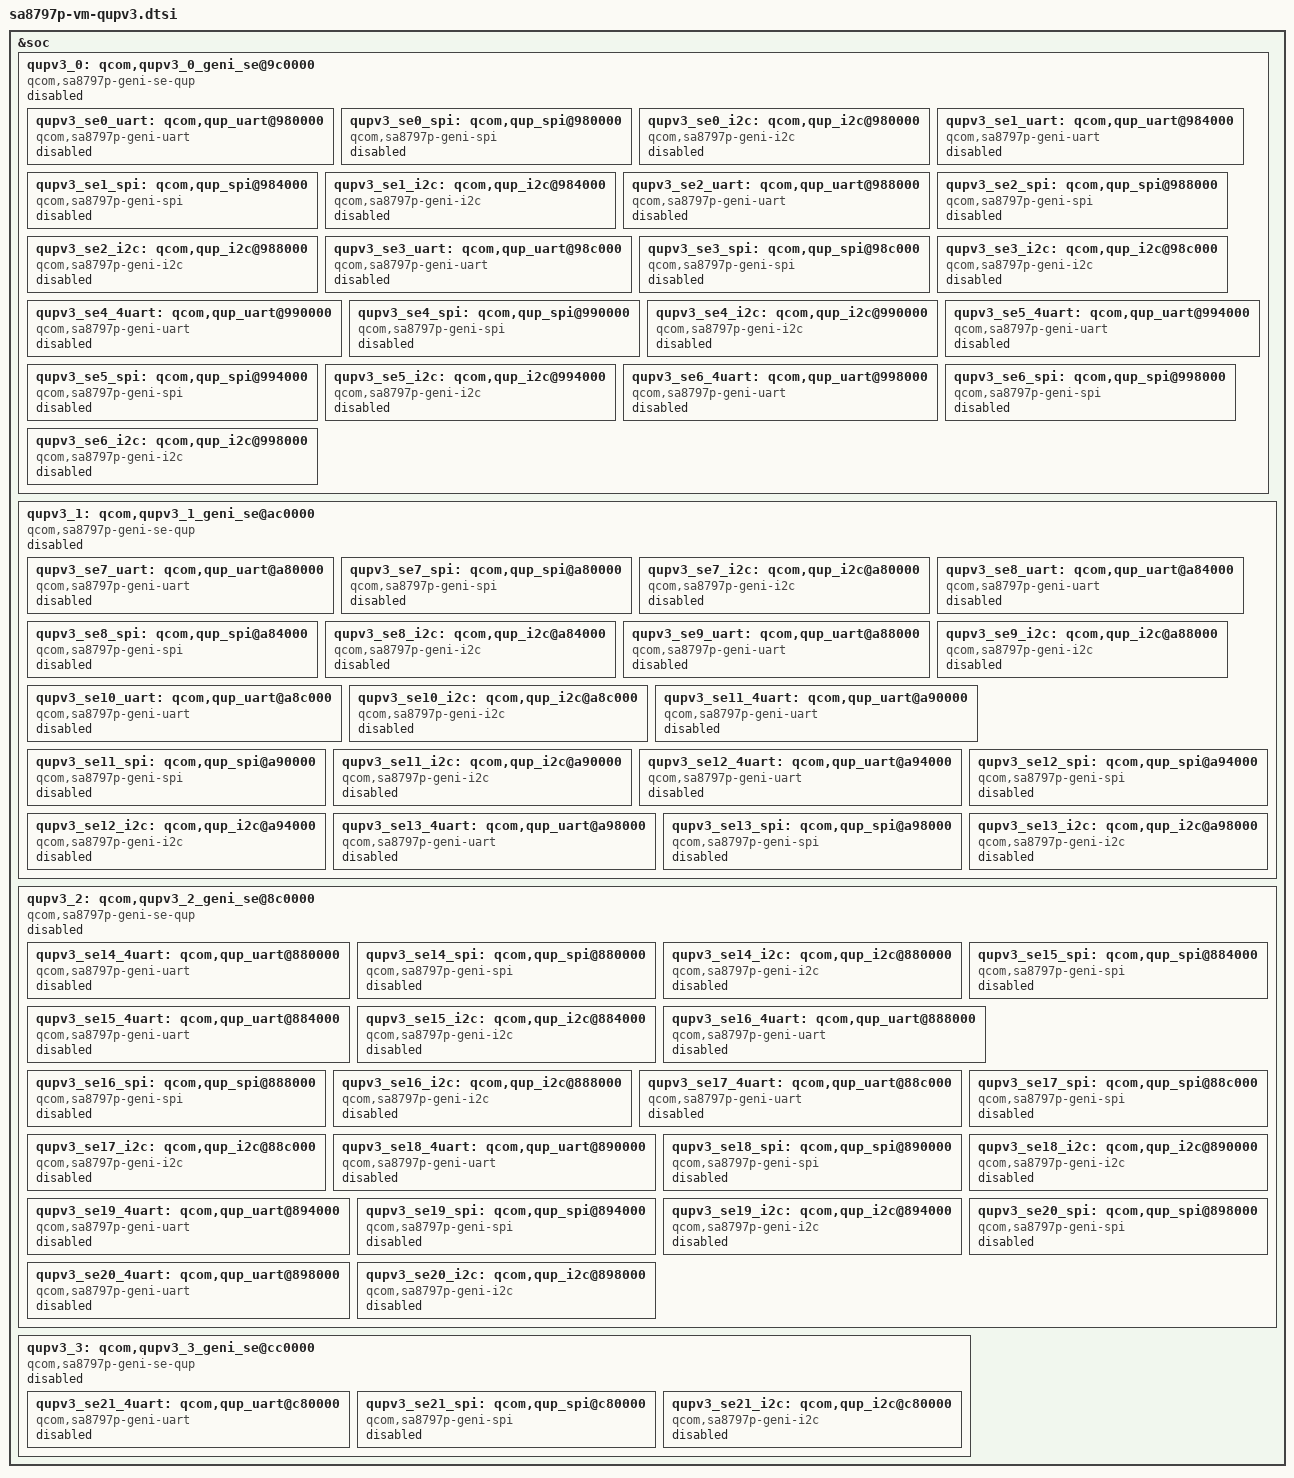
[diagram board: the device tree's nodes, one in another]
// SPDX-License-Identifier: BSD-3-Clause
/*
 * Copyright (c) Qualcomm Technologies, Inc. and/or its subsidiaries.
 */

/* Note :
 * power-domains = <&scmi_power x>, <&scmi_perf x>;
 * These values should be adjusted as per PVM (QNX/Linux) while configuring passthrough.
 */

&soc {
	/* QUPv3_0  wrapper  instance */
	qupv3_0: qcom,qupv3_0_geni_se@9c0000 {
		compatible = "qcom,sa8797p-geni-se-qup", "qcom,sa8255p-geni-se-qup";
		reg = <0x9c0000 0x1000>;
		#address-cells = <1>;
		#size-cells = <1>;
		ranges;
		iommus = <&apps_smmu_2 0x1018 0x0>;
		qcom,iommu-dma = "default";
		status = "disabled";

		qupv3_se0_uart: qcom,qup_uart@980000 {
			compatible = "qcom,sa8797p-geni-uart", "qcom,sa8255p-geni-uart";
			reg = <0x980000 0x3000>;
			interrupts = <GIC_SPI 314 IRQ_TYPE_LEVEL_HIGH>;
			power-domains = <&scmi_power 0>, <&scmi_perf 0>;
			power-domain-names = "power", "perf";
			status = "disabled";
		};

		qupv3_se0_spi: qcom,qup_spi@980000 {
			compatible = "qcom,sa8797p-geni-spi", "qcom,sa8255p-geni-spi";
			reg = <0x980000 0x3000>;
			interrupts = <GIC_SPI 314 IRQ_TYPE_LEVEL_HIGH>;
			power-domains = <&scmi_power 0>, <&scmi_perf 0>;
			power-domain-names = "power", "perf";
			status = "disabled";
		};

		qupv3_se0_i2c: qcom,qup_i2c@980000 {
			compatible = "qcom,sa8797p-geni-i2c", "qcom,sa8255p-geni-i2c";
			reg = <0x980000 0x3000>;
			interrupts = <GIC_SPI 314 IRQ_TYPE_LEVEL_HIGH>;
			power-domains = <&scmi_power 0>;
			status = "disabled";
		};

		qupv3_se1_uart: qcom,qup_uart@984000 {
			compatible = "qcom,sa8797p-geni-uart", "qcom,sa8255p-geni-uart";
			reg = <0x984000 0x3000>;
			interrupts = <GIC_SPI 513 IRQ_TYPE_LEVEL_HIGH>;
			power-domains = <&scmi_power 1>, <&scmi_perf 1>;
			power-domain-names = "power", "perf";
			status = "disabled";
		};

		qupv3_se1_spi: qcom,qup_spi@984000 {
			compatible = "qcom,sa8797p-geni-spi", "qcom,sa8255p-geni-spi";
			reg = <0x984000 0x3000>;
			interrupts = <GIC_SPI 513 IRQ_TYPE_LEVEL_HIGH>;
			power-domains = <&scmi_power 1>, <&scmi_perf 1>;
			power-domain-names = "power", "perf";
			status = "disabled";
		};

		qupv3_se1_i2c: qcom,qup_i2c@984000 {
			compatible = "qcom,sa8797p-geni-i2c", "qcom,sa8255p-geni-i2c";
			reg = <0x984000 0x3000>;
			interrupts = <GIC_SPI 513 IRQ_TYPE_LEVEL_HIGH>;
			power-domains = <&scmi_power 1>;
			status = "disabled";
		};

		qupv3_se2_uart: qcom,qup_uart@988000 {
			compatible = "qcom,sa8797p-geni-uart", "qcom,sa8255p-geni-uart";
			reg = <0x988000 0x3000>;
			interrupts = <GIC_SPI 514 IRQ_TYPE_LEVEL_HIGH>;
			power-domains = <&scmi_power 2>, <&scmi_perf 2>;
			power-domain-names = "power", "perf";
			status = "disabled";
		};

		qupv3_se2_spi: qcom,qup_spi@988000 {
			compatible = "qcom,sa8797p-geni-spi", "qcom,sa8255p-geni-spi";
			reg = <0x988000 0x3000>;
			interrupts = <GIC_SPI 514 IRQ_TYPE_LEVEL_HIGH>;
			power-domains = <&scmi_power 2>, <&scmi_perf 2>;
			power-domain-names = "power", "perf";
			status = "disabled";
		};

		qupv3_se2_i2c: qcom,qup_i2c@988000 {
			compatible = "qcom,sa8797p-geni-i2c", "qcom,sa8255p-geni-i2c";
			reg = <0x988000 0x3000>;
			interrupts = <GIC_SPI 514 IRQ_TYPE_LEVEL_HIGH>;
			power-domains = <&scmi_power 2>;
			status = "disabled";
		};

		qupv3_se3_uart: qcom,qup_uart@98c000 {
			compatible = "qcom,sa8797p-geni-uart", "qcom,sa8255p-geni-uart";
			reg = <0x98c000 0x3000>;
			interrupts = <GIC_SPI 515 IRQ_TYPE_LEVEL_HIGH>;
			power-domains = <&scmi_power 3>, <&scmi_perf 3>;
			power-domain-names = "power", "perf";
			status = "disabled";
		};

		qupv3_se3_spi: qcom,qup_spi@98c000 {
			compatible = "qcom,sa8797p-geni-spi", "qcom,sa8255p-geni-spi";
			reg = <0x98c000 0x3000>;
			interrupts = <GIC_SPI 515 IRQ_TYPE_LEVEL_HIGH>;
			power-domains = <&scmi_power 3>, <&scmi_perf 3>;
			power-domain-names = "power", "perf";
			status = "disabled";
		};

		qupv3_se3_i2c: qcom,qup_i2c@98c000 {
			compatible = "qcom,sa8797p-geni-i2c", "qcom,sa8255p-geni-i2c";
			reg = <0x98c000 0x3000>;
			interrupts = <GIC_SPI 515 IRQ_TYPE_LEVEL_HIGH>;
			power-domains = <&scmi_power 3>;
			status = "disabled";
		};

		qupv3_se4_4uart: qcom,qup_uart@990000 {
			compatible = "qcom,sa8797p-geni-uart", "qcom,sa8255p-geni-uart";
			reg = <0x990000 0x3000>;
			interrupts = <GIC_SPI 516 IRQ_TYPE_LEVEL_HIGH>;
			power-domains = <&scmi_power 4>, <&scmi_perf 4>;
			power-domain-names = "power", "perf";
			status = "disabled";
		};

		qupv3_se4_spi: qcom,qup_spi@990000 {
			compatible = "qcom,sa8797p-geni-spi", "qcom,sa8255p-geni-spi";
			reg = <0x990000 0x3000>;
			interrupts = <GIC_SPI 516 IRQ_TYPE_LEVEL_HIGH>;
			power-domains = <&scmi_power 4>, <&scmi_perf 4>;
			power-domain-names = "power", "perf";
			status = "disabled";
		};

		qupv3_se4_i2c: qcom,qup_i2c@990000 {
			compatible = "qcom,sa8797p-geni-i2c", "qcom,sa8255p-geni-i2c";
			reg = <0x990000 0x3000>;
			interrupts = <GIC_SPI 516 IRQ_TYPE_LEVEL_HIGH>;
			power-domains = <&scmi_power 4>;
			status = "disabled";
		};

		qupv3_se5_4uart: qcom,qup_uart@994000 {
			compatible = "qcom,sa8797p-geni-uart", "qcom,sa8255p-geni-uart";
			reg = <0x994000 0x3000>;
			interrupts = <GIC_SPI 517 IRQ_TYPE_LEVEL_HIGH>;
			power-domains = <&scmi_power 5>, <&scmi_perf 5>;
			power-domain-names = "power", "perf";
			status = "disabled";
		};

		qupv3_se5_spi: qcom,qup_spi@994000 {
			compatible = "qcom,sa8797p-geni-spi", "qcom,sa8255p-geni-spi";
			reg = <0x994000 0x3000>;
			interrupts = <GIC_SPI 517 IRQ_TYPE_LEVEL_HIGH>;
			power-domains = <&scmi_power 5>, <&scmi_perf 5>;
			power-domain-names = "power", "perf";
			status = "disabled";
		};

		qupv3_se5_i2c: qcom,qup_i2c@994000 {
			compatible = "qcom,sa8797p-geni-i2c", "qcom,sa8255p-geni-i2c";
			reg = <0x994000 0x3000>;
			interrupts = <GIC_SPI 517 IRQ_TYPE_LEVEL_HIGH>;
			power-domains = <&scmi_power 5>;
			status = "disabled";
		};

		qupv3_se6_4uart: qcom,qup_uart@998000 {
			compatible = "qcom,sa8797p-geni-uart", "qcom,sa8255p-geni-uart";
			reg = <0x998000 0x3000>;
			interrupts = <GIC_SPI 518 IRQ_TYPE_LEVEL_HIGH>;
			power-domains = <&scmi_power 6>, <&scmi_perf 6>;
			power-domain-names = "power", "perf";
			status = "disabled";
		};

		qupv3_se6_spi: qcom,qup_spi@998000 {
			compatible = "qcom,sa8797p-geni-spi", "qcom,sa8255p-geni-spi";
			reg = <0x998000 0x3000>;
			interrupts = <GIC_SPI 518 IRQ_TYPE_LEVEL_HIGH>;
			power-domains = <&scmi_power 6>, <&scmi_perf 6>;
			power-domain-names = "power", "perf";
			status = "disabled";
		};

		qupv3_se6_i2c: qcom,qup_i2c@998000 {
			compatible = "qcom,sa8797p-geni-i2c", "qcom,sa8255p-geni-i2c";
			reg = <0x998000 0x3000>;
			interrupts = <GIC_SPI 518 IRQ_TYPE_LEVEL_HIGH>;
			power-domains = <&scmi_power 6>;
			status = "disabled";
		};
	};

	/* QUPv3_1  wrapper  instance */
	qupv3_1: qcom,qupv3_1_geni_se@ac0000 {
		compatible = "qcom,sa8797p-geni-se-qup", "qcom,sa8255p-geni-se-qup";
		reg = <0xac0000 0x1000>;
		#address-cells = <1>;
		#size-cells = <1>;
		ranges;
		iommus = <&apps_smmu_2 0x1058 0x0>;
		qcom,iommu-dma = "default";
		status = "disabled";

		qupv3_se7_uart: qcom,qup_uart@a80000 {
			compatible = "qcom,sa8797p-geni-uart", "qcom,sa8255p-geni-uart";
			reg = <0xa80000 0x3000>;
			interrupts = <GIC_SPI 353 IRQ_TYPE_LEVEL_HIGH>;
			power-domains = <&scmi_power 7>, <&scmi_perf 7>;
			power-domain-names = "power", "perf";
			status = "disabled";
		};

		qupv3_se7_spi: qcom,qup_spi@a80000 {
			compatible = "qcom,sa8797p-geni-spi", "qcom,sa8255p-geni-spi";
			reg = <0xa80000 0x3000>;
			interrupts = <GIC_SPI 353 IRQ_TYPE_LEVEL_HIGH>;
			power-domains = <&scmi_power 7>, <&scmi_perf 7>;
			power-domain-names = "power", "perf";
			status = "disabled";
		};

		qupv3_se7_i2c: qcom,qup_i2c@a80000 {
			compatible = "qcom,sa8797p-geni-i2c", "qcom,sa8255p-geni-i2c";
			reg = <0xa80000 0x3000>;
			interrupts = <GIC_SPI 353 IRQ_TYPE_LEVEL_HIGH>;
			power-domains = <&scmi_power 7>;
			status = "disabled";
		};

		qupv3_se8_uart: qcom,qup_uart@a84000 {
			compatible = "qcom,sa8797p-geni-uart", "qcom,sa8255p-geni-uart";
			reg = <0xa84000 0x3000>;
			interrupts = <GIC_SPI 354 IRQ_TYPE_LEVEL_HIGH>;
			power-domains = <&scmi_power 8>, <&scmi_perf 8>;
			power-domain-names = "power", "perf";
			status = "disabled";
		};

		qupv3_se8_spi: qcom,qup_spi@a84000 {
			compatible = "qcom,sa8797p-geni-spi", "qcom,sa8255p-geni-spi";
			reg = <0xa84000 0x3000>;
			interrupts = <GIC_SPI 354 IRQ_TYPE_LEVEL_HIGH>;
			power-domains = <&scmi_power 8>, <&scmi_perf 8>;
			power-domain-names = "power", "perf";
			status = "disabled";
		};

		qupv3_se8_i2c: qcom,qup_i2c@a84000 {
			compatible = "qcom,sa8797p-geni-i2c", "qcom,sa8255p-geni-i2c";
			reg = <0xa84000 0x3000>;
			interrupts = <GIC_SPI 354 IRQ_TYPE_LEVEL_HIGH>;
			power-domains = <&scmi_power 8>;
			status = "disabled";
		};

		qupv3_se9_uart: qcom,qup_uart@a88000 {
			compatible = "qcom,sa8797p-geni-uart", "qcom,sa8255p-geni-uart";
			reg = <0xa88000 0x3000>;
			interrupts = <GIC_SPI 355 IRQ_TYPE_LEVEL_HIGH>;
			power-domains = <&scmi_power 9>, <&scmi_perf 9>;
			power-domain-names = "power", "perf";
			status = "disabled";
		};

		qupv3_se9_i2c: qcom,qup_i2c@a88000 {
			compatible = "qcom,sa8797p-geni-i2c", "qcom,sa8255p-geni-i2c";
			reg = <0xa88000 0x3000>;
			interrupts = <GIC_SPI 355 IRQ_TYPE_LEVEL_HIGH>;
			power-domains = <&scmi_power 9>;
			status = "disabled";
		};

		qupv3_se10_uart: qcom,qup_uart@a8c000 {
			compatible = "qcom,sa8797p-geni-uart", "qcom,sa8255p-geni-uart";
			reg = <0xa8c000 0x3000>;
			interrupts = <GIC_SPI 356 IRQ_TYPE_LEVEL_HIGH>;
			power-domains = <&scmi_power 10>, <&scmi_perf 10>;
			power-domain-names = "power", "perf";
			status = "disabled";
		};

		qupv3_se10_i2c: qcom,qup_i2c@a8c000 {
			compatible = "qcom,sa8797p-geni-i2c", "qcom,sa8255p-geni-i2c";
			reg = <0xa8c000 0x3000>;
			interrupts = <GIC_SPI 356 IRQ_TYPE_LEVEL_HIGH>;
			power-domains = <&scmi_power 10>;
			status = "disabled";
		};

		qupv3_se11_4uart: qcom,qup_uart@a90000 {
			compatible = "qcom,sa8797p-geni-uart", "qcom,sa8255p-geni-uart";
			reg = <0xa90000 0x3000>;
			interrupts = <GIC_SPI 357 IRQ_TYPE_LEVEL_HIGH>;
			power-domains = <&scmi_power 11>, <&scmi_perf 11>;
			power-domain-names = "power", "perf";
			status = "disabled";
		};

		qupv3_se11_spi: qcom,qup_spi@a90000 {
			compatible = "qcom,sa8797p-geni-spi", "qcom,sa8255p-geni-spi";
			reg = <0xa90000 0x3000>;
			interrupts = <GIC_SPI 357 IRQ_TYPE_LEVEL_HIGH>;
			power-domains = <&scmi_power 11>, <&scmi_perf 11>;
			power-domain-names = "power", "perf";
			status = "disabled";
		};

		qupv3_se11_i2c: qcom,qup_i2c@a90000 {
			compatible = "qcom,sa8797p-geni-i2c", "qcom,sa8255p-geni-i2c";
			reg = <0xa90000 0x3000>;
			interrupts = <GIC_SPI 357 IRQ_TYPE_LEVEL_HIGH>;
			power-domains = <&scmi_power 11>;
			status = "disabled";
		};

		qupv3_se12_4uart: qcom,qup_uart@a94000 {
			compatible = "qcom,sa8797p-geni-uart", "qcom,sa8255p-geni-uart";
			reg = <0xa94000 0x3000>;
			interrupts = <GIC_SPI 358 IRQ_TYPE_LEVEL_HIGH>;
			power-domains = <&scmi_power 12>, <&scmi_perf 12>;
			power-domain-names = "power", "perf";
			status = "disabled";
		};

		qupv3_se12_spi: qcom,qup_spi@a94000 {
			compatible = "qcom,sa8797p-geni-spi", "qcom,sa8255p-geni-spi";
			reg = <0xa94000 0x3000>;
			interrupts = <GIC_SPI 358 IRQ_TYPE_LEVEL_HIGH>;
			power-domains = <&scmi_power 12>, <&scmi_perf 12>;
			power-domain-names = "power", "perf";
			status = "disabled";
		};

		qupv3_se12_i2c: qcom,qup_i2c@a94000 {
			compatible = "qcom,sa8797p-geni-i2c", "qcom,sa8255p-geni-i2c";
			reg = <0xa94000 0x3000>;
			interrupts = <GIC_SPI 358 IRQ_TYPE_LEVEL_HIGH>;
			power-domains = <&scmi_power 12>;
			status = "disabled";
		};

		qupv3_se13_4uart: qcom,qup_uart@a98000 {
			compatible = "qcom,sa8797p-geni-uart", "qcom,sa8255p-geni-uart";
			reg = <0xa98000 0x3000>;
			interrupts = <GIC_SPI 363 IRQ_TYPE_LEVEL_HIGH>;
			power-domains = <&scmi_power 13>, <&scmi_perf 13>;
			power-domain-names = "power", "perf";
			status = "disabled";
		};

		qupv3_se13_spi: qcom,qup_spi@a98000 {
			compatible = "qcom,sa8797p-geni-spi", "qcom,sa8255p-geni-spi";
			reg = <0xa98000 0x3000>;
			interrupts = <GIC_SPI 363 IRQ_TYPE_LEVEL_HIGH>;
			power-domains = <&scmi_power 13>, <&scmi_perf 13>;
			power-domain-names = "power", "perf";
			status = "disabled";
		};

		qupv3_se13_i2c: qcom,qup_i2c@a98000 {
			compatible = "qcom,sa8797p-geni-i2c", "qcom,sa8255p-geni-i2c";
			reg = <0xa98000 0x3000>;
			interrupts = <GIC_SPI 363 IRQ_TYPE_LEVEL_HIGH>;
			power-domains = <&scmi_power 13>;
			status = "disabled";
		};
	};

	/* QUPv3_2  wrapper  instance */
	qupv3_2: qcom,qupv3_2_geni_se@8c0000 {
		compatible = "qcom,sa8797p-geni-se-qup", "qcom,sa8255p-geni-se-qup";
		reg = <0x8c0000 0x1000>;
		#address-cells = <1>;
		#size-cells = <1>;
		ranges;
		iommus = <&apps_smmu_0 0x15b8 0x0>;
		qcom,iommu-dma = "default";
		status = "disabled";

		/* 2BT UART Instance */
		qupv3_se14_4uart: qcom,qup_uart@880000 {
			compatible = "qcom,sa8797p-geni-uart", "qcom,sa8255p-geni-uart";
			reg = <0x880000 0x3000>;
			interrupts = <GIC_SPI 373 IRQ_TYPE_LEVEL_HIGH>;
			power-domains = <&scmi_power 14>, <&scmi_perf 14>;
			power-domain-names = "power", "perf";
			status = "disabled";
		};

		qupv3_se14_spi: qcom,qup_spi@880000 {
			compatible = "qcom,sa8797p-geni-spi", "qcom,sa8255p-geni-spi";
			reg = <0x880000 0x3000>;
			interrupts = <GIC_SPI 373 IRQ_TYPE_LEVEL_HIGH>;
			power-domains = <&scmi_power 14>, <&scmi_perf 14>;
			power-domain-names = "power", "perf";
			status = "disabled";
		};

		qupv3_se14_i2c: qcom,qup_i2c@880000 {
			compatible = "qcom,sa8797p-geni-i2c", "qcom,sa8255p-geni-i2c";
			reg = <0x880000 0x3000>;
			interrupts = <GIC_SPI 373 IRQ_TYPE_LEVEL_HIGH>;
			power-domains = <&scmi_power 14>;
			status = "disabled";
		};

		qupv3_se15_4uart: qcom,qup_uart@884000 {
			compatible = "qcom,sa8797p-geni-uart", "qcom,sa8255p-geni-uart";
			reg = <0x884000 0x3000>;
			interrupts = <GIC_SPI 583 IRQ_TYPE_LEVEL_HIGH>;
			power-domains = <&scmi_power 15>, <&scmi_perf 15>;
			power-domain-names = "power", "perf";
			status = "disabled";
		};

		qupv3_se15_spi: qcom,qup_spi@884000 {
			compatible = "qcom,sa8797p-geni-spi", "qcom,sa8255p-geni-spi";
			reg = <0x884000 0x3000>;
			interrupts = <GIC_SPI 583 IRQ_TYPE_LEVEL_HIGH>;
			power-domains = <&scmi_power 15>, <&scmi_perf 15>;
			power-domain-names = "power", "perf";
			status = "disabled";
		};

		qupv3_se15_i2c: qcom,qup_i2c@884000 {
			compatible = "qcom,sa8797p-geni-i2c", "qcom,sa8255p-geni-i2c";
			reg = <0x884000 0x3000>;
			interrupts = <GIC_SPI 583 IRQ_TYPE_LEVEL_HIGH>;
			power-domains = <&scmi_power 15>;
			status = "disabled";
		};

		qupv3_se16_4uart: qcom,qup_uart@888000 {
			compatible = "qcom,sa8797p-geni-uart", "qcom,sa8255p-geni-uart";
			reg = <0x888000 0x3000>;
			interrupts = <GIC_SPI 584 IRQ_TYPE_LEVEL_HIGH>;
			power-domains = <&scmi_power 16>, <&scmi_perf 16>;
			power-domain-names = "power", "perf";
			status = "disabled";
		};

		qupv3_se16_spi: qcom,qup_spi@888000 {
			compatible = "qcom,sa8797p-geni-spi", "qcom,sa8255p-geni-spi";
			reg = <0x888000 0x3000>;
			interrupts = <GIC_SPI 584 IRQ_TYPE_LEVEL_HIGH>;
			power-domains = <&scmi_power 16>, <&scmi_perf 16>;
			power-domain-names = "power", "perf";
			status = "disabled";
		};

		qupv3_se16_i2c: qcom,qup_i2c@888000 {
			compatible = "qcom,sa8797p-geni-i2c", "qcom,sa8255p-geni-i2c";
			reg = <0x888000 0x3000>;
			interrupts = <GIC_SPI 584 IRQ_TYPE_LEVEL_HIGH>;
			power-domains = <&scmi_power 16>;
			status = "disabled";
		};

		/* BT UART Instance */
		qupv3_se17_4uart: qcom,qup_uart@88c000 {
			compatible = "qcom,sa8797p-geni-uart", "qcom,sa8255p-geni-uart";
			reg = <0x88c000 0x3000>;
			interrupts = <GIC_SPI 585 IRQ_TYPE_LEVEL_HIGH>;
			power-domains = <&scmi_power 17>, <&scmi_perf 17>;
			power-domain-names = "power", "perf";
			status = "disabled";
		};

		qupv3_se17_spi: qcom,qup_spi@88c000 {
			compatible = "qcom,sa8797p-geni-spi", "qcom,sa8255p-geni-spi";
			reg = <0x88c000 0x3000>;
			interrupts = <GIC_SPI 585 IRQ_TYPE_LEVEL_HIGH>;
			power-domains = <&scmi_power 17>, <&scmi_perf 17>;
			power-domain-names = "power", "perf";
			status = "disabled";
		};

		qupv3_se17_i2c: qcom,qup_i2c@88c000 {
			compatible = "qcom,sa8797p-geni-i2c", "qcom,sa8255p-geni-i2c";
			reg = <0x88c000 0x3000>;
			interrupts = <GIC_SPI 585 IRQ_TYPE_LEVEL_HIGH>;
			power-domains = <&scmi_power 17>;
			status = "disabled";
		};

		qupv3_se18_4uart: qcom,qup_uart@890000 {
			compatible = "qcom,sa8797p-geni-uart", "qcom,sa8255p-geni-uart";
			reg = <0x890000 0x3000>;
			interrupts = <GIC_SPI 586 IRQ_TYPE_LEVEL_HIGH>;
			power-domains = <&scmi_power 18>, <&scmi_perf 18>;
			power-domain-names = "power", "perf";
			status = "disabled";
		};

		qupv3_se18_spi: qcom,qup_spi@890000 {
			compatible = "qcom,sa8797p-geni-spi", "qcom,sa8255p-geni-spi";
			reg = <0x890000 0x3000>;
			interrupts = <GIC_SPI 586 IRQ_TYPE_LEVEL_HIGH>;
			power-domains = <&scmi_power 18>, <&scmi_perf 18>;
			power-domain-names = "power", "perf";
			status = "disabled";
		};

		qupv3_se18_i2c: qcom,qup_i2c@890000 {
			compatible = "qcom,sa8797p-geni-i2c", "qcom,sa8255p-geni-i2c";
			reg = <0x890000 0x3000>;
			interrupts = <GIC_SPI 586 IRQ_TYPE_LEVEL_HIGH>;
			power-domains = <&scmi_power 18>;
			status = "disabled";
		};

		qupv3_se19_4uart: qcom,qup_uart@894000 {
			compatible = "qcom,sa8797p-geni-uart", "qcom,sa8255p-geni-uart";
			reg = <0x894000 0x3000>;
			interrupts = <GIC_SPI 587 IRQ_TYPE_LEVEL_HIGH>;
			power-domains = <&scmi_power 19>, <&scmi_perf 19>;
			power-domain-names = "power", "perf";
			status = "disabled";
		};

		qupv3_se19_spi: qcom,qup_spi@894000 {
			compatible = "qcom,sa8797p-geni-spi", "qcom,sa8255p-geni-spi";
			reg = <0x894000 0x3000>;
			interrupts = <GIC_SPI 587 IRQ_TYPE_LEVEL_HIGH>;
			power-domains = <&scmi_power 19>, <&scmi_perf 19>;
			power-domain-names = "power", "perf";
			status = "disabled";
		};

		qupv3_se19_i2c: qcom,qup_i2c@894000 {
			compatible = "qcom,sa8797p-geni-i2c", "qcom,sa8255p-geni-i2c";
			reg = <0x894000 0x3000>;
			interrupts = <GIC_SPI 587 IRQ_TYPE_LEVEL_HIGH>;
			power-domains = <&scmi_power 19>;
			status = "disabled";
		};

		qupv3_se20_4uart: qcom,qup_uart@898000 {
			compatible = "qcom,sa8797p-geni-uart", "qcom,sa8255p-geni-uart";
			reg = <0x898000 0x3000>;
			interrupts = <GIC_SPI 461 IRQ_TYPE_LEVEL_HIGH>;
			power-domains = <&scmi_power 20>, <&scmi_perf 20>;
			power-domain-names = "power", "perf";
			status = "disabled";
		};

		qupv3_se20_spi: qcom,qup_spi@898000 {
			compatible = "qcom,sa8797p-geni-spi", "qcom,sa8255p-geni-spi";
			reg = <0x898000 0x3000>;
			interrupts = <GIC_SPI 461 IRQ_TYPE_LEVEL_HIGH>;
			power-domains = <&scmi_power 20>, <&scmi_perf 20>;
			power-domain-names = "power", "perf";
			status = "disabled";
		};

		qupv3_se20_i2c: qcom,qup_i2c@898000 {
			compatible = "qcom,sa8797p-geni-i2c", "qcom,sa8255p-geni-i2c";
			reg = <0x898000 0x3000>;
			interrupts = <GIC_SPI 461 IRQ_TYPE_LEVEL_HIGH>;
			power-domains = <&scmi_power 20>;
			status = "disabled";
		};
	};

	qupv3_3: qcom,qupv3_3_geni_se@cc0000 {
		compatible = "qcom,sa8797p-geni-se-qup", "qcom,sa8255p-geni-se-qup";
		reg = <0xcc0000 0x1000>;
		#address-cells = <1>;
		#size-cells = <1>;
		ranges;
		iommus = <&apps_smmu_0 0x1078 0x0>;
		qcom,iommu-dma = "default";
		status = "disabled";

		qupv3_se21_4uart: qcom,qup_uart@c80000 {
			compatible = "qcom,sa8797p-geni-uart", "qcom,sa8255p-geni-uart";
			reg = <0xc80000 0x3000>;
			interrupts = <GIC_SPI 312 IRQ_TYPE_LEVEL_HIGH>;
			power-domains = <&scmi_power 21>, <&scmi_perf 21>;
			power-domain-names = "power", "perf";
			status = "disabled";
		};

		qupv3_se21_spi: qcom,qup_spi@c80000 {
			compatible = "qcom,sa8797p-geni-spi", "qcom,sa8255p-geni-spi";
			reg = <0xc80000 0x3000>;
			interrupts = <GIC_SPI 312 IRQ_TYPE_LEVEL_HIGH>;
			power-domains = <&scmi_power 21>, <&scmi_perf 21>;
			power-domain-names = "power", "perf";
			status = "disabled";
		};

		qupv3_se21_i2c: qcom,qup_i2c@c80000 {
			compatible = "qcom,sa8797p-geni-i2c", "qcom,sa8255p-geni-i2c";
			reg = <0xc80000 0x3000>;
			interrupts = <GIC_SPI 312 IRQ_TYPE_LEVEL_HIGH>;
			power-domains = <&scmi_power 21>;
			status = "disabled";
		};
	};
};
